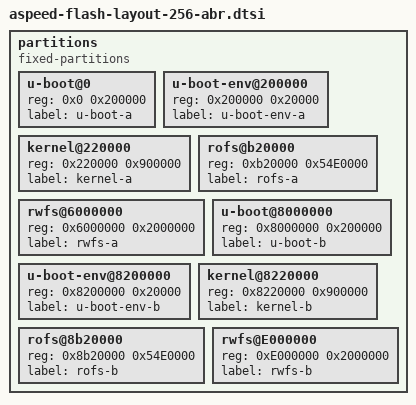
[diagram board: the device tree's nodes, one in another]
// SPDX-License-Identifier: GPL-2.0+

partitions {
	compatible = "fixed-partitions";
	#address-cells = <1>;
	#size-cells = <1>;

	u-boot@0 {
		reg = <0x0 0x200000>; // 2MB
		label = "u-boot-a";
	};

	u-boot-env@200000 {
		reg = <0x200000 0x20000>; // 128KB
		label = "u-boot-env-a";
	};

	kernel@220000 {
		reg = <0x220000 0x900000>; // 9MB
		label = "kernel-a";
	};

	rofs@b20000 {
		reg = <0xb20000 0x54E0000>; // 84.875MB
		label = "rofs-a";
	};

	rwfs@6000000 {
		reg = <0x6000000 0x2000000>; // 32MB
		label = "rwfs-a";
	};

	u-boot@8000000 {
		reg = <0x8000000 0x200000>; // 2MB
		label = "u-boot-b";
	};

	u-boot-env@8200000 {
		reg = <0x8200000 0x20000>; // 128KB
		label = "u-boot-env-b";
	};

	kernel@8220000 {
		reg = <0x8220000 0x900000>; // 9MB
		label = "kernel-b";
	};

	rofs@8b20000 {
		reg = <0x8b20000 0x54E0000>; // 84.875MB
		label = "rofs-b";
	};

	rwfs@E000000 {
		reg = <0xE000000 0x2000000>; // 32MB
		label = "rwfs-b";
	};
};
